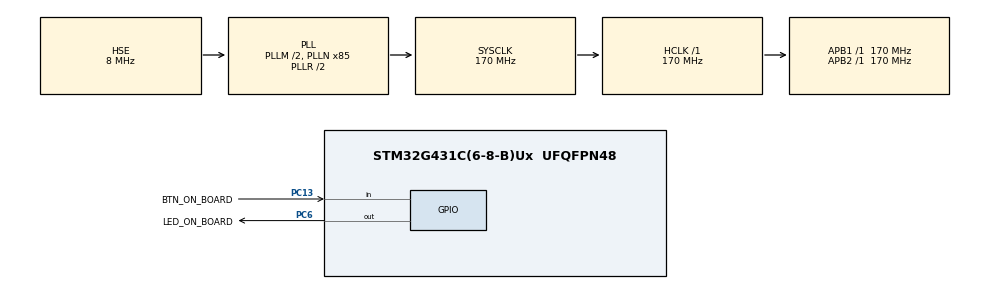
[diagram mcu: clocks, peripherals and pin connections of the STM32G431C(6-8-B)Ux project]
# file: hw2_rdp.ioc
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Mcu.Family=STM32G4
Mcu.Name=STM32G431C(6-8-B)Ux
Mcu.Package=UFQFPN48
NVIC.PriorityGroup=NVIC_PRIORITYGROUP_4
PA13.Mode=Serial_Wire
PA13.Signal=SYS_JTMS-SWDIO
PA14.Mode=Serial_Wire
PA14.Signal=SYS_JTCK-SWCLK
PC13.GPIO_Label=BTN_ON_BOARD
PC13.GPIO_PuPd=GPIO_PULLDOWN
PC13.Signal=GPIO_Input
PC14-OSC32_IN.Mode=LSE-External-Oscillator
PC14-OSC32_IN.Signal=RCC_OSC32_IN
PC15-OSC32_OUT.Mode=LSE-External-Oscillator
PC15-OSC32_OUT.Signal=RCC_OSC32_OUT
PC6.GPIO_Label=LED_ON_BOARD
PC6.Signal=GPIO_Output
PF0-OSC_IN.Mode=HSE-External-Oscillator
PF0-OSC_IN.Signal=RCC_OSC_IN
PF1-OSC_OUT.Mode=HSE-External-Oscillator
PF1-OSC_OUT.Signal=RCC_OSC_OUT
ProjectManager.HeapSize=0x200
ProjectManager.StackSize=0x400
ProjectManager.TargetToolchain=STM32CubeIDE
RCC.ADC12Freq_Value=170000000
RCC.AHBFreq_Value=170000000
RCC.APB1Freq_Value=170000000
RCC.APB1TimFreq_Value=170000000
RCC.APB2Freq_Value=170000000
RCC.APB2TimFreq_Value=170000000
RCC.CortexFreq_Value=170000000
RCC.EXTERNAL_CLOCK_VALUE=12288000
RCC.HCLKFreq_Value=170000000
RCC.HSE_VALUE=8000000
RCC.HSI48_VALUE=48000000
RCC.HSI_VALUE=16000000
RCC.PLLM=RCC_PLLM_DIV2
RCC.PLLN=85
RCC.PLLSourceVirtual=RCC_PLLSOURCE_HSE
RCC.SYSCLKFreq_VALUE=170000000
RCC.SYSCLKSource=RCC_SYSCLKSOURCE_PLLCLK
RCC.USBFreq_Value=170000000
RCC.VCOOutputFreq_Value=340000000
VP_SYS_VS_DBSignals.Mode=DisableDeadBatterySignals
board=custom

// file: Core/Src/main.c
/* USER CODE BEGIN Header */
/**
  ******************************************************************************
  * @file           : main.c
  * @brief          : Main program body
  ******************************************************************************
  * @attention
  *
  * Copyright (c) 2025 STMicroelectronics.
  * All rights reserved.
  *
  * This software is licensed under terms that can be found in the LICENSE file
  * in the root directory of this software component.
  * If no LICENSE file comes with this software, it is provided AS-IS.
  *
  ******************************************************************************
  */
/* USER CODE END Header */
#include "main.h"

void SystemClock_Config(void);
static void MX_GPIO_Init(void);
/* USER CODE BEGIN PFP */

void set_rdp_lvl_one(void)
{
  FLASH_OBProgramInitTypeDef FLASH_OBInitStruct;

  HAL_FLASH_Unlock();
  HAL_FLASH_OB_Unlock();

  HAL_FLASHEx_OBGetConfig(&FLASH_OBInitStruct);

  FLASH_OBInitStruct.OptionType = OPTIONBYTE_RDP;
  FLASH_OBInitStruct.RDPLevel = OB_RDP_LEVEL_1;

  HAL_FLASHEx_OBProgram(&FLASH_OBInitStruct);

  HAL_FLASH_OB_Launch();

  HAL_FLASH_OB_Lock();
  HAL_FLASH_Lock();

}

/* USER CODE END PFP */

int main(void)
{

  /* MCU Configuration--------------------------------------------------------*/

  /* Reset of all peripherals, Initializes the Flash interface and the Systick. */
  HAL_Init();

  /* Configure the system clock */
  SystemClock_Config();

  /* Initialize all configured peripherals */
  MX_GPIO_Init();

  /* Infinite loop */
  /* USER CODE BEGIN WHILE */
  HAL_GPIO_WritePin(LED_ON_BOARD_GPIO_Port, LED_ON_BOARD_Pin, GPIO_PIN_RESET);

  while (1)
  {

    if(HAL_GPIO_ReadPin(BTN_ON_BOARD_GPIO_Port, BTN_ON_BOARD_Pin) == GPIO_PIN_SET)
    {
      HAL_GPIO_WritePin(LED_ON_BOARD_GPIO_Port, LED_ON_BOARD_Pin, GPIO_PIN_SET);
      set_rdp_lvl_one();
    }

    /* USER CODE END WHILE */

  }
}

void SystemClock_Config(void)
{
  RCC_OscInitTypeDef RCC_OscInitStruct = {0};
  RCC_ClkInitTypeDef RCC_ClkInitStruct = {0};

  /** Configure the main internal regulator output voltage
  */
  HAL_PWREx_ControlVoltageScaling(PWR_REGULATOR_VOLTAGE_SCALE1_BOOST);

  /** Initializes the RCC Oscillators according to the specified parameters
  * in the RCC_OscInitTypeDef structure.
  */
  RCC_OscInitStruct.OscillatorType = RCC_OSCILLATORTYPE_HSE;
  RCC_OscInitStruct.HSEState = RCC_HSE_ON;
  RCC_OscInitStruct.PLL.PLLState = RCC_PLL_ON;
  RCC_OscInitStruct.PLL.PLLSource = RCC_PLLSOURCE_HSE;
  RCC_OscInitStruct.PLL.PLLM = RCC_PLLM_DIV2;
  RCC_OscInitStruct.PLL.PLLN = 85;
  RCC_OscInitStruct.PLL.PLLP = RCC_PLLP_DIV2;
  RCC_OscInitStruct.PLL.PLLQ = RCC_PLLQ_DIV2;
  RCC_OscInitStruct.PLL.PLLR = RCC_PLLR_DIV2;
  if (HAL_RCC_OscConfig(&RCC_OscInitStruct) != HAL_OK)
  {
    Error_Handler();
  }

  /** Initializes the CPU, AHB and APB buses clocks
  */
  RCC_ClkInitStruct.ClockType = RCC_CLOCKTYPE_HCLK|RCC_CLOCKTYPE_SYSCLK
                              |RCC_CLOCKTYPE_PCLK1|RCC_CLOCKTYPE_PCLK2;
  RCC_ClkInitStruct.SYSCLKSource = RCC_SYSCLKSOURCE_PLLCLK;
  RCC_ClkInitStruct.AHBCLKDivider = RCC_SYSCLK_DIV1;
  RCC_ClkInitStruct.APB1CLKDivider = RCC_HCLK_DIV1;
  RCC_ClkInitStruct.APB2CLKDivider = RCC_HCLK_DIV1;

  if (HAL_RCC_ClockConfig(&RCC_ClkInitStruct, FLASH_LATENCY_4) != HAL_OK)
  {
    Error_Handler();
  }
}

static void MX_GPIO_Init(void)
{
  GPIO_InitTypeDef GPIO_InitStruct = {0};

  /* GPIO Ports Clock Enable */
  __HAL_RCC_GPIOC_CLK_ENABLE();
  __HAL_RCC_GPIOF_CLK_ENABLE();
  __HAL_RCC_GPIOA_CLK_ENABLE();

  /*Configure GPIO pin Output Level */
  HAL_GPIO_WritePin(LED_ON_BOARD_GPIO_Port, LED_ON_BOARD_Pin, GPIO_PIN_RESET);

  /*Configure GPIO pin : BTN_ON_BOARD_Pin */
  GPIO_InitStruct.Pin = BTN_ON_BOARD_Pin;
  GPIO_InitStruct.Mode = GPIO_MODE_INPUT;
  GPIO_InitStruct.Pull = GPIO_PULLDOWN;
  HAL_GPIO_Init(BTN_ON_BOARD_GPIO_Port, &GPIO_InitStruct);

  /*Configure GPIO pin : LED_ON_BOARD_Pin */
  GPIO_InitStruct.Pin = LED_ON_BOARD_Pin;
  GPIO_InitStruct.Mode = GPIO_MODE_OUTPUT_PP;
  GPIO_InitStruct.Pull = GPIO_NOPULL;
  GPIO_InitStruct.Speed = GPIO_SPEED_FREQ_LOW;
  HAL_GPIO_Init(LED_ON_BOARD_GPIO_Port, &GPIO_InitStruct);

}

void Error_Handler(void)
{
  __disable_irq();
  while (1)
  {
  }
}
